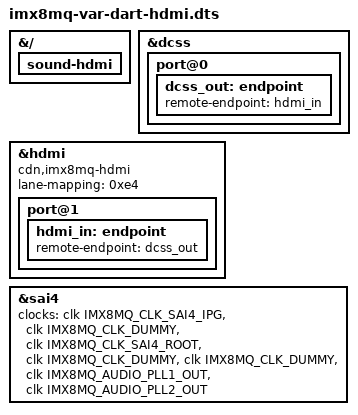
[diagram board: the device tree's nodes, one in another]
// SPDX-License-Identifier: (GPL-2.0 OR MIT)
/*
 * Device tree overlay to support HDMI on DART-MX8M
 *
 * Copyright 2017 NXP
 * Copyright 2018-2024 Variscite Ltd.
 */

/dts-v1/;
/plugin/;

#include <dt-bindings/clock/imx8mq-clock.h>

&{/} {
	sound-hdmi {
		status = "okay";
	};
};

&dcss {
	status = "okay";

	port@0 {
		dcss_out: endpoint {
			  remote-endpoint = <&hdmi_in>;
		};
	};
};

&hdmi {
	compatible = "cdn,imx8mq-hdmi";
	lane-mapping = <0xe4>;
	status = "okay";
	port@1 {
		hdmi_in: endpoint {
			remote-endpoint = <&dcss_out>;
		};
	};
};

&sai4 {
	clocks = <&clk IMX8MQ_CLK_SAI4_IPG>, <&clk IMX8MQ_CLK_DUMMY>,
		<&clk IMX8MQ_CLK_SAI4_ROOT>, <&clk IMX8MQ_CLK_DUMMY>,
		<&clk IMX8MQ_CLK_DUMMY>, <&clk IMX8MQ_AUDIO_PLL1_OUT>,
		<&clk IMX8MQ_AUDIO_PLL2_OUT>;
	clock-names = "bus", "mclk0", "mclk1", "mclk2", "mclk3", "pll8k", "pll11k";
	status = "okay";
};
